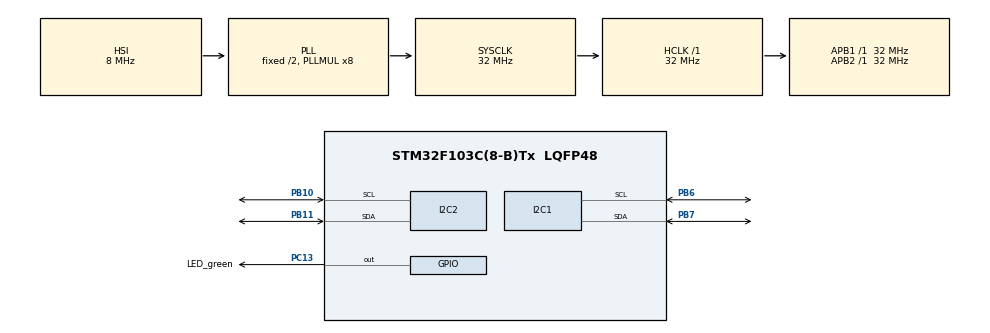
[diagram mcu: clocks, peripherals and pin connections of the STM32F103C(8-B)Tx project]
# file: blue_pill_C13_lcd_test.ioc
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FREERTOS.Tasks01=defaultTask,0,128,StartDefaultTask,Default,NULL,Dynamic,NULL,NULL;LEDblink,-3,128,LEDblinkTask,Default,NULL,Dynamic,NULL,NULL
Mcu.Family=STM32F1
Mcu.Name=STM32F103C(8-B)Tx
Mcu.Package=LQFP48
NVIC.PriorityGroup=NVIC_PRIORITYGROUP_4
NVIC.TIM4_IRQn=true\:0\:0\:false\:false\:true\:false\:false\:true
NVIC.TimeBase=TIM4_IRQn
NVIC.TimeBaseIP=TIM4
PA13.Mode=Serial_Wire
PA13.Signal=SYS_JTMS-SWDIO
PA14.Mode=Serial_Wire
PA14.Signal=SYS_JTCK-SWCLK
PB10.Mode=I2C
PB10.Signal=I2C2_SCL
PB11.Mode=I2C
PB11.Signal=I2C2_SDA
PB6.Mode=I2C
PB6.Signal=I2C1_SCL
PB7.Mode=I2C
PB7.Signal=I2C1_SDA
PC13-TAMPER-RTC.GPIO_Label=LED_green
PC13-TAMPER-RTC.Signal=GPIO_Output
ProjectManager.HeapSize=0x200
ProjectManager.StackSize=0x400
ProjectManager.TargetToolchain=MDK-ARM V5.27
RCC.AHBFreq_Value=32000000
RCC.APB1Freq_Value=32000000
RCC.APB1TimFreq_Value=32000000
RCC.APB2Freq_Value=32000000
RCC.APB2TimFreq_Value=32000000
RCC.HCLKFreq_Value=32000000
RCC.PLLMUL=RCC_PLL_MUL8
RCC.SYSCLKFreq_VALUE=32000000
RCC.SYSCLKSource=RCC_SYSCLKSOURCE_PLLCLK
RCC.USBFreq_Value=32000000
VP_FREERTOS_VS_CMSIS_V1.Mode=CMSIS_V1
VP_SYS_VS_tim4.Mode=TIM4
VP_TIM3_VS_ClockSourceINT.Mode=Internal
VP_TIM3_VS_OPM.Mode=OPM_bit
board=custom

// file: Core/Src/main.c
/* USER CODE BEGIN Header */
/**
  ******************************************************************************
  * @file           : main.c
  * @brief          : Main program body
  ******************************************************************************
  * @attention
  *
  * <h2><center>&copy; Copyright (c) 2020 STMicroelectronics.
  * All rights reserved.</center></h2>
  *
  * This software component is licensed by ST under Ultimate Liberty license
  * SLA0044, the "License"; You may not use this file except in compliance with
  * the License. You may obtain a copy of the License at:
  *                             www.st.com/SLA0044
  *
  ******************************************************************************
  */
/* USER CODE END Header */

#include "main.h"
#include "cmsis_os.h"

I2C_HandleTypeDef hi2c1;
I2C_HandleTypeDef hi2c2;

TIM_HandleTypeDef htim3;

osThreadId defaultTaskHandle;
osThreadId LEDblinkHandle;
/* USER CODE BEGIN PV */

uint8_t		address = ADDRESS_2004;

/* USER CODE END PV */

void SystemClock_Config(void);
static void MX_GPIO_Init(void);
static void MX_I2C1_Init(void);
static void MX_I2C2_Init(void);
static void MX_TIM3_Init(void);
void StartDefaultTask(void const * argument);
void LEDblinkTask(void const * argument);

/* USER CODE BEGIN PFP */

//void	display_2004_i2c_init(void);
//void	E_pulse(void);

/* USER CODE END PFP */

int main(void)
{

  /* MCU Configuration--------------------------------------------------------*/

  /* Reset of all peripherals, Initializes the Flash interface and the Systick. */
  HAL_Init();

  /* Configure the system clock */
  SystemClock_Config();

  /* Initialize all configured peripherals */
  MX_GPIO_Init();
  MX_I2C1_Init();
  MX_I2C2_Init();
  MX_TIM3_Init();
  /* USER CODE BEGIN 2 */

	delay_init();
	display_2004_i2c_init(&hi2c2);

  /* USER CODE END 2 */

  /* Create the thread(s) */
  /* definition and creation of defaultTask */
  osThreadDef(defaultTask, StartDefaultTask, osPriorityNormal, 0, 128);
  defaultTaskHandle = osThreadCreate(osThread(defaultTask), NULL);

  /* definition and creation of LEDblink */
  osThreadDef(LEDblink, LEDblinkTask, osPriorityIdle, 0, 128);
  LEDblinkHandle = osThreadCreate(osThread(LEDblink), NULL);

  /* Start scheduler */
  osKernelStart();

  /* We should never get here as control is now taken by the scheduler */

  /* Infinite loop */
  while (1)
  {

  }
}

void SystemClock_Config(void)
{
  RCC_OscInitTypeDef RCC_OscInitStruct = {0};
  RCC_ClkInitTypeDef RCC_ClkInitStruct = {0};

  /** Initializes the CPU, AHB and APB busses clocks
  */
  RCC_OscInitStruct.OscillatorType = RCC_OSCILLATORTYPE_HSI;
  RCC_OscInitStruct.HSIState = RCC_HSI_ON;
  RCC_OscInitStruct.HSICalibrationValue = RCC_HSICALIBRATION_DEFAULT;
  RCC_OscInitStruct.PLL.PLLState = RCC_PLL_ON;
  RCC_OscInitStruct.PLL.PLLSource = RCC_PLLSOURCE_HSI_DIV2;
  RCC_OscInitStruct.PLL.PLLMUL = RCC_PLL_MUL8;
  if (HAL_RCC_OscConfig(&RCC_OscInitStruct) != HAL_OK)
  {
    Error_Handler();
  }
  /** Initializes the CPU, AHB and APB busses clocks
  */
  RCC_ClkInitStruct.ClockType = RCC_CLOCKTYPE_HCLK|RCC_CLOCKTYPE_SYSCLK
                              |RCC_CLOCKTYPE_PCLK1|RCC_CLOCKTYPE_PCLK2;
  RCC_ClkInitStruct.SYSCLKSource = RCC_SYSCLKSOURCE_PLLCLK;
  RCC_ClkInitStruct.AHBCLKDivider = RCC_SYSCLK_DIV1;
  RCC_ClkInitStruct.APB1CLKDivider = RCC_HCLK_DIV1;
  RCC_ClkInitStruct.APB2CLKDivider = RCC_HCLK_DIV1;

  if (HAL_RCC_ClockConfig(&RCC_ClkInitStruct, FLASH_LATENCY_1) != HAL_OK)
  {
    Error_Handler();
  }
}

static void MX_I2C1_Init(void)
{

  hi2c1.Instance = I2C1;
  hi2c1.Init.ClockSpeed = 100000;
  hi2c1.Init.DutyCycle = I2C_DUTYCYCLE_2;
  hi2c1.Init.OwnAddress1 = 0;
  hi2c1.Init.AddressingMode = I2C_ADDRESSINGMODE_7BIT;
  hi2c1.Init.DualAddressMode = I2C_DUALADDRESS_DISABLE;
  hi2c1.Init.OwnAddress2 = 0;
  hi2c1.Init.GeneralCallMode = I2C_GENERALCALL_DISABLE;
  hi2c1.Init.NoStretchMode = I2C_NOSTRETCH_DISABLE;
  if (HAL_I2C_Init(&hi2c1) != HAL_OK)
  {
    Error_Handler();
  }

}

static void MX_I2C2_Init(void)
{

  hi2c2.Instance = I2C2;
  hi2c2.Init.ClockSpeed = 100000;
  hi2c2.Init.DutyCycle = I2C_DUTYCYCLE_2;
  hi2c2.Init.OwnAddress1 = 0;
  hi2c2.Init.AddressingMode = I2C_ADDRESSINGMODE_7BIT;
  hi2c2.Init.DualAddressMode = I2C_DUALADDRESS_DISABLE;
  hi2c2.Init.OwnAddress2 = 0;
  hi2c2.Init.GeneralCallMode = I2C_GENERALCALL_DISABLE;
  hi2c2.Init.NoStretchMode = I2C_NOSTRETCH_DISABLE;
  if (HAL_I2C_Init(&hi2c2) != HAL_OK)
  {
    Error_Handler();
  }

}

static void MX_TIM3_Init(void)
{

  TIM_ClockConfigTypeDef sClockSourceConfig = {0};
  TIM_MasterConfigTypeDef sMasterConfig = {0};

  htim3.Instance = TIM3;
  htim3.Init.Prescaler = 0;
  htim3.Init.CounterMode = TIM_COUNTERMODE_UP;
  htim3.Init.Period = 0;
  htim3.Init.ClockDivision = TIM_CLOCKDIVISION_DIV1;
  htim3.Init.AutoReloadPreload = TIM_AUTORELOAD_PRELOAD_DISABLE;
  if (HAL_TIM_Base_Init(&htim3) != HAL_OK)
  {
    Error_Handler();
  }
  sClockSourceConfig.ClockSource = TIM_CLOCKSOURCE_INTERNAL;
  if (HAL_TIM_ConfigClockSource(&htim3, &sClockSourceConfig) != HAL_OK)
  {
    Error_Handler();
  }
  if (HAL_TIM_OnePulse_Init(&htim3, TIM_OPMODE_SINGLE) != HAL_OK)
  {
    Error_Handler();
  }
  sMasterConfig.MasterOutputTrigger = TIM_TRGO_RESET;
  sMasterConfig.MasterSlaveMode = TIM_MASTERSLAVEMODE_DISABLE;
  if (HAL_TIMEx_MasterConfigSynchronization(&htim3, &sMasterConfig) != HAL_OK)
  {
    Error_Handler();
  }

}

static void MX_GPIO_Init(void)
{
  GPIO_InitTypeDef GPIO_InitStruct = {0};

  /* GPIO Ports Clock Enable */
  __HAL_RCC_GPIOC_CLK_ENABLE();
  __HAL_RCC_GPIOB_CLK_ENABLE();
  __HAL_RCC_GPIOA_CLK_ENABLE();

  /*Configure GPIO pin Output Level */
  HAL_GPIO_WritePin(LED_green_GPIO_Port, LED_green_Pin, GPIO_PIN_RESET);

  /*Configure GPIO pin : LED_green_Pin */
  GPIO_InitStruct.Pin = LED_green_Pin;
  GPIO_InitStruct.Mode = GPIO_MODE_OUTPUT_PP;
  GPIO_InitStruct.Pull = GPIO_NOPULL;
  GPIO_InitStruct.Speed = GPIO_SPEED_FREQ_LOW;
  HAL_GPIO_Init(LED_green_GPIO_Port, &GPIO_InitStruct);

}

void StartDefaultTask(void const * argument)
{
  for(;;)
  {
    osDelay(1);
  }
}

void LEDblinkTask(void const * argument)
{
  /* USER CODE BEGIN LEDblinkTask */
  /* Infinite loop */
  for(;;)
  {
		HAL_GPIO_TogglePin(LED_green_GPIO_Port, LED_green_Pin);
    osDelay(1000);
  }
  /* USER CODE END LEDblinkTask */
}

void HAL_TIM_PeriodElapsedCallback(TIM_HandleTypeDef *htim)
{
  if (htim->Instance == TIM4) {
    HAL_IncTick();
  }
}

void Error_Handler(void)
{
}

/************************ (C) COPYRIGHT STMicroelectronics *****END OF FILE****/
